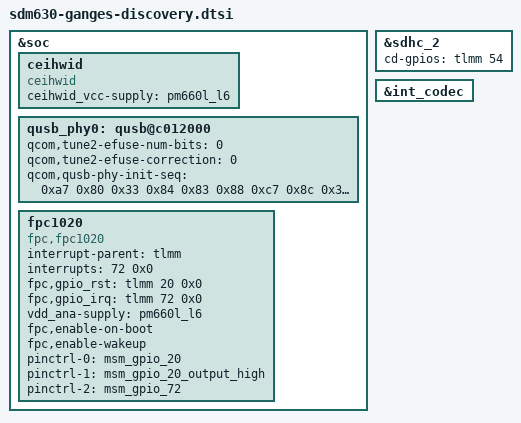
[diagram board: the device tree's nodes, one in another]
/* arch/arm64/boot/dts/somc/sdm630-ganges-discovery.dtsi
 *
 * This program is free software; you can redistribute it and/or modify
 * it under the terms of the GNU General Public License version 2 and
 * only version 2 as published by the Free Software Foundation.
 *
 * This program is distributed in the hope that it will be useful,
 * but WITHOUT ANY WARRANTY; without even the implied warranty of
 * MERCHANTABILITY or FITNESS FOR A PARTICULAR PURPOSE.  See the
 * GNU General Public License for more details.
*/

#include "sdm630-ganges-common.dtsi"
#include "display/dsi-panel-discovery.dtsi"
#include "sdm630-ganges-touch.dtsi"
#include "camera/sdm630-ganges-discovery-camera-sensor.dtsi"
#include "battery/charger-ganges-discovery.dtsi"

&soc {
	ceihwid {
		compatible = "ceihwid";
		ceihwid_vcc-supply = <&pm660l_l6>;
	};

	qusb_phy0: qusb@c012000 {
		qcom,tune2-efuse-num-bits = <0>;
		qcom,tune2-efuse-correction = <0>;
		qcom,qusb-phy-init-seq = <0xa7 0x80
			0x33 0x84
			0x83 0x88
			0xc7 0x8c
			0x30 0x08
			0x79 0x0c
			0x21 0x10
			0x14 0x9c
			0x9f 0x1c
			0x00 0x18>;
	};

	fpc1020 {
		status = "ok";
		compatible = "fpc,fpc1020";
		interrupt-parent = <&tlmm>;
		interrupts = <72 0x0>;
		fpc,gpio_rst    = <&tlmm 20 0x0>;
		fpc,gpio_irq    = <&tlmm 72 0x0>;
		vdd_ana-supply = <&pm660l_l6>;
		fpc,enable-on-boot;
		fpc,enable-wakeup;
		pinctrl-names = "fpc1020_reset_reset",
				"fpc1020_reset_active",
				"fpc1020_irq_active";
		pinctrl-0 = <&msm_gpio_20>;
		pinctrl-1 = <&msm_gpio_20_output_high>;
		pinctrl-2 = <&msm_gpio_72>;
	};
};

&sdhc_2 {
	cd-gpios = <&tlmm 54 0x0>;
};

&int_codec {
	/delete-property/ qcom,msm-micbias2-ext-cap;
};
